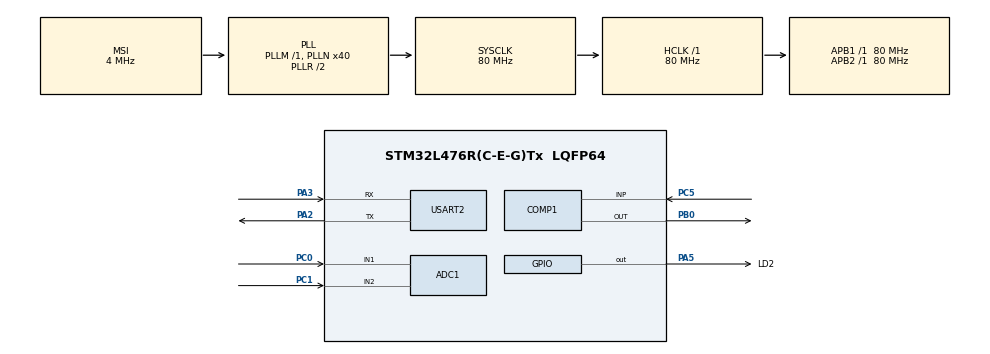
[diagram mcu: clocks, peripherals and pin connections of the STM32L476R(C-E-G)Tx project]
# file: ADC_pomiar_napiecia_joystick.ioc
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ADC1.Channel-1\#ChannelRegularConversion=ADC_CHANNEL_1
ADC1.Channel-2\#ChannelRegularConversion=ADC_CHANNEL_2
ADC1.ContinuousConvMode=ENABLE
ADC1.DMAContinuousRequests=ENABLE
ADC1.LowPowerAutoWait=DISABLE
ADC1.NbrOfConversion=2
ADC1.NbrOfConversionFlag=1
ADC1.OffsetNumber-1\#ChannelRegularConversion=ADC_OFFSET_NONE
ADC1.OffsetNumber-2\#ChannelRegularConversion=ADC_OFFSET_NONE
ADC1.Overrun=ADC_OVR_DATA_OVERWRITTEN
ADC1.OversamplingMode=ENABLE
ADC1.Rank-1\#ChannelRegularConversion=1
ADC1.Rank-2\#ChannelRegularConversion=2
ADC1.Ratio=ADC_OVERSAMPLING_RATIO_16
ADC1.RightBitShift=ADC_RIGHTBITSHIFT_4
ADC1.SamplingTime-1\#ChannelRegularConversion=ADC_SAMPLETIME_640CYCLES_5
ADC1.SamplingTime-2\#ChannelRegularConversion=ADC_SAMPLETIME_640CYCLES_5
ADC1.master=1
COMP1.OutputPol=COMP_OUTPUTPOL_INVERTED
Dma.ADC1.0.Direction=DMA_PERIPH_TO_MEMORY
Dma.ADC1.0.Instance=DMA1_Channel1
Dma.ADC1.0.MemDataAlignment=DMA_MDATAALIGN_HALFWORD
Dma.ADC1.0.MemInc=DMA_MINC_ENABLE
Dma.ADC1.0.Mode=DMA_CIRCULAR
Dma.ADC1.0.PeriphDataAlignment=DMA_PDATAALIGN_HALFWORD
Dma.ADC1.0.PeriphInc=DMA_PINC_DISABLE
Dma.ADC1.0.Priority=DMA_PRIORITY_LOW
Dma.Request0=ADC1
Mcu.Family=STM32L4
Mcu.Name=STM32L476R(C-E-G)Tx
Mcu.Package=LQFP64
NVIC.DMA1_Channel1_IRQn=true\:2\:0\:true\:false\:true\:false\:true\:true
NVIC.PriorityGroup=NVIC_PRIORITYGROUP_4
PA13\ (JTMS-SWDIO).Mode=Serial_Wire
PA13\ (JTMS-SWDIO).Signal=SYS_JTMS-SWDIO
PA14\ (JTCK-SWCLK).Mode=Serial_Wire
PA14\ (JTCK-SWCLK).Signal=SYS_JTCK-SWCLK
PA2.Mode=Asynchronous
PA2.Signal=USART2_TX
PA3.Mode=Asynchronous
PA3.Signal=USART2_RX
PA5.GPIO_Label=LD2
PA5.Signal=GPIO_Output
PB0.Mode=ExternalOutput
PB0.Signal=COMP1_OUT
PC0.Signal=ADCx_IN1
PC1.Signal=ADCx_IN2
PC5.Mode=INP
PC5.Signal=COMP1_INP
ProjectManager.HeapSize=0x200
ProjectManager.StackSize=0x400
ProjectManager.TargetToolchain=STM32CubeIDE
RCC.ADCFreq_Value=32000000
RCC.AHBFreq_Value=80000000
RCC.APB1Freq_Value=80000000
RCC.APB1TimFreq_Value=80000000
RCC.APB2Freq_Value=80000000
RCC.APB2TimFreq_Value=80000000
RCC.CortexFreq_Value=80000000
RCC.HCLKFreq_Value=80000000
RCC.HSE_VALUE=8000000
RCC.HSI_VALUE=16000000
RCC.LSE_VALUE=32768
RCC.MSI_VALUE=4000000
RCC.PLLN=40
RCC.PLLSAI1N=16
RCC.SYSCLKFreq_VALUE=80000000
RCC.SYSCLKSource=RCC_SYSCLKSOURCE_PLLCLK
RCC.USBFreq_Value=32000000
RCC.VCOOutputFreq_Value=160000000
SH.ADCx_IN1.0=ADC1_IN1,IN1-Single-Ended
SH.ADCx_IN2.0=ADC1_IN2,IN2-Single-Ended
USART2.VirtualMode-Asynchronous=VM_ASYNC
VP_COMP1_VS_DACOUT1.Mode=INM_DACOUT1
VP_DAC1_VS_DACI1.Mode=DAC_OUT1_Int
board=custom

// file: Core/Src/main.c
/* USER CODE BEGIN Header */
/**
  ******************************************************************************
  * @file           : main.c
  * @brief          : Main program body
  ******************************************************************************
  * @attention
  *
  * Copyright (c) 2024 STMicroelectronics.
  * All rights reserved.
  *
  * This software is licensed under terms that can be found in the LICENSE file
  * in the root directory of this software component.
  * If no LICENSE file comes with this software, it is provided AS-IS.
  *
  ******************************************************************************
  */
/* USER CODE END Header */
#include "main.h"

/* USER CODE BEGIN Includes */
#include <stdio.h>

/* USER CODE END Includes */

ADC_HandleTypeDef hadc1;
DMA_HandleTypeDef hdma_adc1;

COMP_HandleTypeDef hcomp1;

DAC_HandleTypeDef hdac1;

UART_HandleTypeDef huart2;

void SystemClock_Config(void);
static void MX_GPIO_Init(void);
static void MX_DMA_Init(void);
static void MX_ADC1_Init(void);
static void MX_USART2_UART_Init(void);
static void MX_COMP1_Init(void);
static void MX_DAC1_Init(void);

/* USER CODE BEGIN 0 */
int __io_putchar(int ch)
{
  if (ch == '\n') {
    __io_putchar('\r');
  }

  HAL_UART_Transmit(&huart2, (uint8_t*)&ch, 1, HAL_MAX_DELAY);

  return 1;
}

volatile static uint16_t joystick[2];
/* USER CODE END 0 */

int main(void)
{

  /* MCU Configuration--------------------------------------------------------*/

  /* Reset of all peripherals, Initializes the Flash interface and the Systick. */
  HAL_Init();

  /* Configure the system clock */
  SystemClock_Config();

  /* Initialize all configured peripherals */
  MX_GPIO_Init();
  MX_DMA_Init();
  MX_ADC1_Init();
  MX_USART2_UART_Init();
  MX_COMP1_Init();
  MX_DAC1_Init();

  /* Infinite loop */
  /* USER CODE BEGIN WHILE */

  /* czekamy na zakończenie poprzedniego pomiaru
  //kalibracja prztwornika ADC
  HAL_ADCEx_Calibration_Start(&hadc1, ADC_SINGLE_ENDED);

  while (1)
  {
	  HAL_ADC_Start(&hadc1);
	  HAL_ADC_PollForConversion(&hadc1, HAL_MAX_DELAY);

	  uint32_t value = HAL_ADC_GetValue(&hadc1);
	  float voltage = 3.3f * value / 4096.0f;

	  printf("ADC = %lu (%.3f V)\n", value, voltage);
	  HAL_Delay(250);
	  */
  //wersja bez czekania - tryb ciągły
  /*
  HAL_ADCEx_Calibration_Start(&hadc1, ADC_SINGLE_ENDED);
  HAL_ADC_Start(&hadc1);

  while (1)
  {
    uint32_t value = HAL_ADC_GetValue(&hadc1);
    float voltage = 3.3f * value / 4096.0f;
    printf("ADC = %lu (%.3f V)\n", value, voltage);

    HAL_Delay(250);
    */
  //2 kanały pomiaru (bez trybu ciągłego), wymaga sporo pracy ze strony procesora
  /*
  HAL_ADCEx_Calibration_Start(&hadc1, ADC_SINGLE_ENDED);

  while (1)
  {
    uint32_t value[2];

    HAL_ADC_Start(&hadc1);
    HAL_ADC_PollForConversion(&hadc1, HAL_MAX_DELAY);
    value[0] = HAL_ADC_GetValue(&hadc1);

    HAL_ADC_Start(&hadc1);
    HAL_ADC_PollForConversion(&hadc1, HAL_MAX_DELAY);
    value[1] = HAL_ADC_GetValue(&hadc1);

    printf("value1=%lu, value2=%lu\n", value[0], value[1]);
    HAL_Delay(250);
    */
  //DMA, czyli Direct Memory Access - jakby dodatkowy prcesor, który kopiuje dane z ADC do pamięci lub gdzieś indziej
  /*
  volatile static uint16_t value[2];

  HAL_ADCEx_Calibration_Start(&hadc1, ADC_SINGLE_ENDED);
  HAL_ADC_Start_DMA(&hadc1, (uint32_t*)value, 2);

  while (1)
  {
    printf("value1=%u, value2=%u\n", value[0], value[1]);

    HAL_Delay(250);
    */
	//obsługa joystick'a
  /*
  HAL_ADCEx_Calibration_Start(&hadc1, ADC_SINGLE_ENDED);
  HAL_ADC_Start_DMA(&hadc1, (uint32_t*)joystick, 2);

  while (1)
  {
    printf("VRx=%u, VRy=%u\n", joystick[0], joystick[1]);
    HAL_Delay(100);
    */

  //DAC - Przetwornik cyfrowo-analogowy oraz komparatora COMP1
  HAL_DAC_Start(&hdac1, DAC_CHANNEL_1);
  HAL_DAC_SetValue(&hdac1, DAC_CHANNEL_1, DAC_ALIGN_12B_R, 3000);

  HAL_COMP_Start(&hcomp1);
  while (1)
  {

    /* USER CODE END WHILE */

  }
}

void SystemClock_Config(void)
{
  RCC_OscInitTypeDef RCC_OscInitStruct = {0};
  RCC_ClkInitTypeDef RCC_ClkInitStruct = {0};

  /** Configure the main internal regulator output voltage
  */
  if (HAL_PWREx_ControlVoltageScaling(PWR_REGULATOR_VOLTAGE_SCALE1) != HAL_OK)
  {
    Error_Handler();
  }

  /** Initializes the RCC Oscillators according to the specified parameters
  * in the RCC_OscInitTypeDef structure.
  */
  RCC_OscInitStruct.OscillatorType = RCC_OSCILLATORTYPE_MSI;
  RCC_OscInitStruct.MSIState = RCC_MSI_ON;
  RCC_OscInitStruct.MSICalibrationValue = 0;
  RCC_OscInitStruct.MSIClockRange = RCC_MSIRANGE_6;
  RCC_OscInitStruct.PLL.PLLState = RCC_PLL_ON;
  RCC_OscInitStruct.PLL.PLLSource = RCC_PLLSOURCE_MSI;
  RCC_OscInitStruct.PLL.PLLM = 1;
  RCC_OscInitStruct.PLL.PLLN = 40;
  RCC_OscInitStruct.PLL.PLLP = RCC_PLLP_DIV7;
  RCC_OscInitStruct.PLL.PLLQ = RCC_PLLQ_DIV2;
  RCC_OscInitStruct.PLL.PLLR = RCC_PLLR_DIV2;
  if (HAL_RCC_OscConfig(&RCC_OscInitStruct) != HAL_OK)
  {
    Error_Handler();
  }

  /** Initializes the CPU, AHB and APB buses clocks
  */
  RCC_ClkInitStruct.ClockType = RCC_CLOCKTYPE_HCLK|RCC_CLOCKTYPE_SYSCLK
                              |RCC_CLOCKTYPE_PCLK1|RCC_CLOCKTYPE_PCLK2;
  RCC_ClkInitStruct.SYSCLKSource = RCC_SYSCLKSOURCE_PLLCLK;
  RCC_ClkInitStruct.AHBCLKDivider = RCC_SYSCLK_DIV1;
  RCC_ClkInitStruct.APB1CLKDivider = RCC_HCLK_DIV1;
  RCC_ClkInitStruct.APB2CLKDivider = RCC_HCLK_DIV1;

  if (HAL_RCC_ClockConfig(&RCC_ClkInitStruct, FLASH_LATENCY_4) != HAL_OK)
  {
    Error_Handler();
  }
}

static void MX_ADC1_Init(void)
{

  ADC_MultiModeTypeDef multimode = {0};
  ADC_ChannelConfTypeDef sConfig = {0};

  /** Common config
  */
  hadc1.Instance = ADC1;
  hadc1.Init.ClockPrescaler = ADC_CLOCK_ASYNC_DIV1;
  hadc1.Init.Resolution = ADC_RESOLUTION_12B;
  hadc1.Init.DataAlign = ADC_DATAALIGN_RIGHT;
  hadc1.Init.ScanConvMode = ADC_SCAN_ENABLE;
  hadc1.Init.EOCSelection = ADC_EOC_SINGLE_CONV;
  hadc1.Init.LowPowerAutoWait = DISABLE;
  hadc1.Init.ContinuousConvMode = ENABLE;
  hadc1.Init.NbrOfConversion = 2;
  hadc1.Init.DiscontinuousConvMode = DISABLE;
  hadc1.Init.ExternalTrigConv = ADC_SOFTWARE_START;
  hadc1.Init.ExternalTrigConvEdge = ADC_EXTERNALTRIGCONVEDGE_NONE;
  hadc1.Init.DMAContinuousRequests = ENABLE;
  hadc1.Init.Overrun = ADC_OVR_DATA_OVERWRITTEN;
  hadc1.Init.OversamplingMode = ENABLE;
  hadc1.Init.Oversampling.Ratio = ADC_OVERSAMPLING_RATIO_16;
  hadc1.Init.Oversampling.RightBitShift = ADC_RIGHTBITSHIFT_4;
  hadc1.Init.Oversampling.TriggeredMode = ADC_TRIGGEREDMODE_SINGLE_TRIGGER;
  hadc1.Init.Oversampling.OversamplingStopReset = ADC_REGOVERSAMPLING_CONTINUED_MODE;
  if (HAL_ADC_Init(&hadc1) != HAL_OK)
  {
    Error_Handler();
  }

  /** Configure the ADC multi-mode
  */
  multimode.Mode = ADC_MODE_INDEPENDENT;
  if (HAL_ADCEx_MultiModeConfigChannel(&hadc1, &multimode) != HAL_OK)
  {
    Error_Handler();
  }

  /** Configure Regular Channel
  */
  sConfig.Channel = ADC_CHANNEL_1;
  sConfig.Rank = ADC_REGULAR_RANK_1;
  sConfig.SamplingTime = ADC_SAMPLETIME_640CYCLES_5;
  sConfig.SingleDiff = ADC_SINGLE_ENDED;
  sConfig.OffsetNumber = ADC_OFFSET_NONE;
  sConfig.Offset = 0;
  if (HAL_ADC_ConfigChannel(&hadc1, &sConfig) != HAL_OK)
  {
    Error_Handler();
  }

  /** Configure Regular Channel
  */
  sConfig.Channel = ADC_CHANNEL_2;
  sConfig.Rank = ADC_REGULAR_RANK_2;
  if (HAL_ADC_ConfigChannel(&hadc1, &sConfig) != HAL_OK)
  {
    Error_Handler();
  }

}

static void MX_COMP1_Init(void)
{

  hcomp1.Instance = COMP1;
  hcomp1.Init.InvertingInput = COMP_INPUT_MINUS_DAC1_CH1;
  hcomp1.Init.NonInvertingInput = COMP_INPUT_PLUS_IO1;
  hcomp1.Init.OutputPol = COMP_OUTPUTPOL_INVERTED;
  hcomp1.Init.Hysteresis = COMP_HYSTERESIS_NONE;
  hcomp1.Init.BlankingSrce = COMP_BLANKINGSRC_NONE;
  hcomp1.Init.Mode = COMP_POWERMODE_HIGHSPEED;
  hcomp1.Init.WindowMode = COMP_WINDOWMODE_DISABLE;
  hcomp1.Init.TriggerMode = COMP_TRIGGERMODE_NONE;
  if (HAL_COMP_Init(&hcomp1) != HAL_OK)
  {
    Error_Handler();
  }

}

static void MX_DAC1_Init(void)
{

  DAC_ChannelConfTypeDef sConfig = {0};

  /** DAC Initialization
  */
  hdac1.Instance = DAC1;
  if (HAL_DAC_Init(&hdac1) != HAL_OK)
  {
    Error_Handler();
  }

  /** DAC channel OUT1 config
  */
  sConfig.DAC_SampleAndHold = DAC_SAMPLEANDHOLD_DISABLE;
  sConfig.DAC_Trigger = DAC_TRIGGER_NONE;
  sConfig.DAC_OutputBuffer = DAC_OUTPUTBUFFER_DISABLE;
  sConfig.DAC_ConnectOnChipPeripheral = DAC_CHIPCONNECT_ENABLE;
  sConfig.DAC_UserTrimming = DAC_TRIMMING_FACTORY;
  if (HAL_DAC_ConfigChannel(&hdac1, &sConfig, DAC_CHANNEL_1) != HAL_OK)
  {
    Error_Handler();
  }

}

static void MX_USART2_UART_Init(void)
{

  huart2.Instance = USART2;
  huart2.Init.BaudRate = 115200;
  huart2.Init.WordLength = UART_WORDLENGTH_8B;
  huart2.Init.StopBits = UART_STOPBITS_1;
  huart2.Init.Parity = UART_PARITY_NONE;
  huart2.Init.Mode = UART_MODE_TX_RX;
  huart2.Init.HwFlowCtl = UART_HWCONTROL_NONE;
  huart2.Init.OverSampling = UART_OVERSAMPLING_16;
  huart2.Init.OneBitSampling = UART_ONE_BIT_SAMPLE_DISABLE;
  huart2.AdvancedInit.AdvFeatureInit = UART_ADVFEATURE_NO_INIT;
  if (HAL_UART_Init(&huart2) != HAL_OK)
  {
    Error_Handler();
  }

}

static void MX_DMA_Init(void)
{

  /* DMA controller clock enable */
  __HAL_RCC_DMA1_CLK_ENABLE();

  /* DMA interrupt init */
  /* DMA1_Channel1_IRQn interrupt configuration */
  HAL_NVIC_SetPriority(DMA1_Channel1_IRQn, 2, 0);
  HAL_NVIC_EnableIRQ(DMA1_Channel1_IRQn);

}

static void MX_GPIO_Init(void)
{
  GPIO_InitTypeDef GPIO_InitStruct = {0};

  /* GPIO Ports Clock Enable */
  __HAL_RCC_GPIOC_CLK_ENABLE();
  __HAL_RCC_GPIOA_CLK_ENABLE();
  __HAL_RCC_GPIOB_CLK_ENABLE();

  /*Configure GPIO pin Output Level */
  HAL_GPIO_WritePin(LD2_GPIO_Port, LD2_Pin, GPIO_PIN_RESET);

  /*Configure GPIO pin : LD2_Pin */
  GPIO_InitStruct.Pin = LD2_Pin;
  GPIO_InitStruct.Mode = GPIO_MODE_OUTPUT_PP;
  GPIO_InitStruct.Pull = GPIO_NOPULL;
  GPIO_InitStruct.Speed = GPIO_SPEED_FREQ_LOW;
  HAL_GPIO_Init(LD2_GPIO_Port, &GPIO_InitStruct);

}

void Error_Handler(void)
{
  __disable_irq();
  while (1)
  {
  }
}
